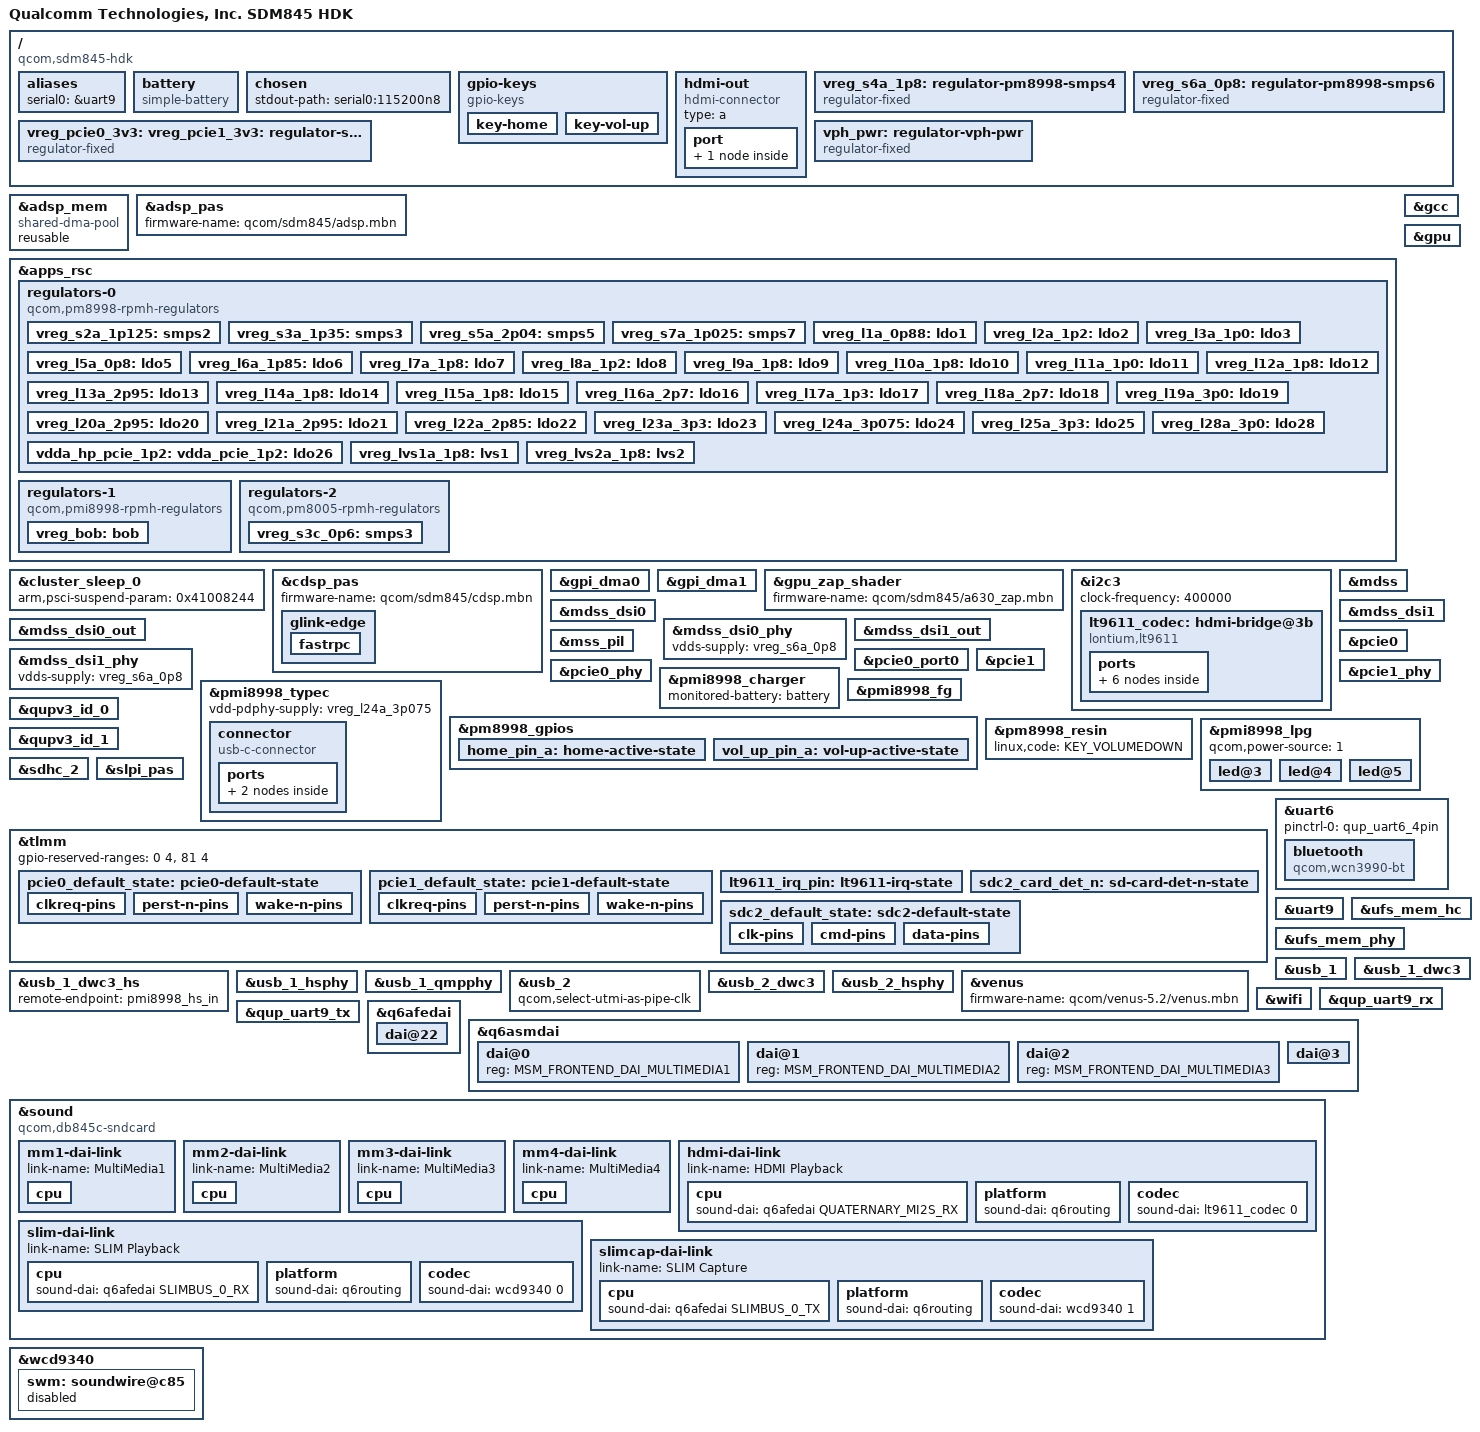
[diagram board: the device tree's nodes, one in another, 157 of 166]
// SPDX-License-Identifier: BSD-3-Clause
/*
 * Copyright (c) Qualcomm Technologies, Inc. and/or its subsidiaries.
 */

/dts-v1/;

#include <dt-bindings/arm/qcom,ids.h>
#include <dt-bindings/input/linux-event-codes.h>
#include <dt-bindings/interrupt-controller/irq.h>
#include <dt-bindings/leds/common.h>
#include <dt-bindings/pinctrl/qcom,pmic-gpio.h>
#include <dt-bindings/regulator/qcom,rpmh-regulator.h>
#include <dt-bindings/sound/qcom,q6afe.h>
#include <dt-bindings/sound/qcom,q6asm.h>
#include <dt-bindings/sound/qcom,wcd934x.h>
#include <dt-bindings/usb/pd.h>

#include "sdm845.dtsi"
#include "sdm845-wcd9340.dtsi"
#include "pm8005.dtsi"
#include "pm8998.dtsi"
#include "pmi8998.dtsi"

/ {
	model = "Qualcomm Technologies, Inc. SDM845 HDK";
	compatible = "qcom,sdm845-hdk", "qcom,sdm845";
	chassis-type = "embedded";

	aliases {
		serial0 = &uart9;
	};
	
	battery: battery {
		compatible = "simple-battery";
	};

	chosen {
		stdout-path = "serial0:115200n8";
	};

	gpio-keys {
		compatible = "gpio-keys";
		autorepeat;

		pinctrl-0 = <&home_pin_a>, <&vol_up_pin_a>;
		pinctrl-names = "default";

		key-home {
			label = "Home";
			linux,code = <KEY_HOMEPAGE>;
			gpios = <&pm8998_gpios 5 GPIO_ACTIVE_LOW>;
		};

		key-vol-up {
			label = "Volume Up";
			linux,code = <KEY_VOLUMEUP>;
			gpios = <&pm8998_gpios 6 GPIO_ACTIVE_LOW>;
		};
	};

	hdmi-out {
		compatible = "hdmi-connector";
		type = "a";

		port {
			hdmi_con: endpoint {
				remote-endpoint = <&lt9611_out>;
			};
		};
	};

	/*
	 * Apparently RPMh does not provide support for PM8998 S4 and S6
	 * because they are always-on; model them as fixed regulators.
	 */
	vreg_s4a_1p8: regulator-pm8998-smps4 {
		compatible = "regulator-fixed";
		regulator-name = "vreg_s4a_1p8";

		regulator-min-microvolt = <1800000>;
		regulator-max-microvolt = <1800000>;

		regulator-always-on;
		regulator-boot-on;

		vin-supply = <&vph_pwr>;
	};

	vreg_s6a_0p8: regulator-pm8998-smps6 {
		compatible = "regulator-fixed";
		regulator-name = "vreg_s6a_0p8";

		regulator-min-microvolt = <800000>;
		regulator-max-microvolt = <800000>;

		regulator-always-on;
		regulator-boot-on;

		vin-supply = <&vph_pwr>;
	};

	vreg_pcie0_3v3:
	vreg_pcie1_3v3:
	vreg_sys_bob_3p3: regulator-sys-bob {
		compatible = "regulator-fixed";
		regulator-name = "sys_bob";
		regulator-min-microvolt = <3300000>;
		regulator-max-microvolt = <3300000>;

		regulator-always-on;
		regulator-boot-on;

		/*
		 * SYS_BOB is powered on by vph_pwr and enabled by S4A_1P8.
		 * This is the least awkward way to describe it.
		 */
		vin-supply = <&vreg_s4a_1p8>;
	};

	vph_pwr: regulator-vph-pwr {
		compatible = "regulator-fixed";
		regulator-name = "vph_pwr";
		regulator-min-microvolt = <3700000>;
		regulator-max-microvolt = <3700000>;
	};
};

&adsp_mem {
	/* Convert the rigid firmware tracking partition into a flexible dynamic DMA pool */
	compatible = "shared-dma-pool";
	reusable;
};

&adsp_pas {
	firmware-name = "qcom/sdm845/adsp.mbn";

	status = "okay";
};

&apps_rsc {
	regulators-0 {
		compatible = "qcom,pm8998-rpmh-regulators";
		qcom,pmic-id = "a";

		vdd-s1-supply = <&vph_pwr>;
		vdd-s2-supply = <&vph_pwr>;
		vdd-s3-supply = <&vph_pwr>;
		vdd-s4-supply = <&vph_pwr>;
		vdd-s5-supply = <&vph_pwr>;
		vdd-s6-supply = <&vph_pwr>;
		vdd-s7-supply = <&vph_pwr>;
		vdd-s8-supply = <&vph_pwr>;
		vdd-s9-supply = <&vph_pwr>;
		vdd-s10-supply = <&vph_pwr>;
		vdd-s11-supply = <&vph_pwr>;
		vdd-s12-supply = <&vph_pwr>;
		vdd-s13-supply = <&vph_pwr>;
		vdd-l1-l27-supply = <&vreg_s7a_1p025>;
		vdd-l2-l8-l17-supply = <&vreg_s3a_1p35>;
		vdd-l3-l11-supply = <&vreg_s7a_1p025>;
		vdd-l4-l5-supply = <&vreg_s7a_1p025>;
		vdd-l6-supply = <&vph_pwr>;
		vdd-l7-l12-l14-l15-supply = <&vreg_s5a_2p04>;
		vdd-l9-supply = <&vreg_bob>;
		vdd-l10-l23-l25-supply = <&vreg_bob>;
		vdd-l13-l19-l21-supply = <&vreg_bob>;
		vdd-l16-l28-supply = <&vreg_bob>;
		vdd-l18-l22-supply = <&vreg_bob>;
		vdd-l20-l24-supply = <&vreg_bob>;
		vdd-l26-supply = <&vreg_s3a_1p35>;
		vin-lvs-1-2-supply = <&vreg_s4a_1p8>;

		vreg_s2a_1p125: smps2 {
			regulator-min-microvolt = <1100000>;
			regulator-max-microvolt = <1100000>;
		};

		vreg_s3a_1p35: smps3 {
			regulator-min-microvolt = <1352000>;
			regulator-max-microvolt = <1352000>;
		};

		vreg_s5a_2p04: smps5 {
			regulator-min-microvolt = <1904000>;
			regulator-max-microvolt = <2040000>;
		};

		vreg_s7a_1p025: smps7 {
			regulator-min-microvolt = <900000>;
			regulator-max-microvolt = <1028000>;
		};

		vreg_l1a_0p88: ldo1 {
			regulator-min-microvolt = <880000>;
			regulator-max-microvolt = <880000>;
			regulator-initial-mode = <RPMH_REGULATOR_MODE_HPM>;
		};

		vreg_l2a_1p2: ldo2 {
			regulator-min-microvolt = <1200000>;
			regulator-max-microvolt = <1200000>;
			regulator-initial-mode = <RPMH_REGULATOR_MODE_HPM>;
			regulator-always-on;
		};

		vreg_l3a_1p0: ldo3 {
			regulator-min-microvolt = <1000000>;
			regulator-max-microvolt = <1000000>;
			regulator-initial-mode = <RPMH_REGULATOR_MODE_HPM>;
		};

		vreg_l5a_0p8: ldo5 {
			regulator-min-microvolt = <800000>;
			regulator-max-microvolt = <800000>;
			regulator-initial-mode = <RPMH_REGULATOR_MODE_HPM>;
		};

		vreg_l6a_1p85: ldo6 {
			regulator-min-microvolt = <1856000>;
			regulator-max-microvolt = <1856000>;
			regulator-initial-mode = <RPMH_REGULATOR_MODE_HPM>;
		};

		vreg_l7a_1p8: ldo7 {
			regulator-min-microvolt = <1800000>;
			regulator-max-microvolt = <1800000>;
			regulator-initial-mode = <RPMH_REGULATOR_MODE_HPM>;
		};

		vreg_l8a_1p2: ldo8 {
			regulator-min-microvolt = <1200000>;
			regulator-max-microvolt = <1248000>;
			regulator-initial-mode = <RPMH_REGULATOR_MODE_HPM>;
		};

		vreg_l9a_1p8: ldo9 {
			regulator-min-microvolt = <1704000>;
			regulator-max-microvolt = <2928000>;
			regulator-initial-mode = <RPMH_REGULATOR_MODE_HPM>;
		};

		vreg_l10a_1p8: ldo10 {
			regulator-min-microvolt = <1704000>;
			regulator-max-microvolt = <2928000>;
			regulator-initial-mode = <RPMH_REGULATOR_MODE_HPM>;
		};

		vreg_l11a_1p0: ldo11 {
			regulator-min-microvolt = <1000000>;
			regulator-max-microvolt = <1048000>;
			regulator-initial-mode = <RPMH_REGULATOR_MODE_HPM>;
		};

		vreg_l12a_1p8: ldo12 {
			regulator-min-microvolt = <1800000>;
			regulator-max-microvolt = <1800000>;
			regulator-initial-mode = <RPMH_REGULATOR_MODE_HPM>;
		};

		vreg_l13a_2p95: ldo13 {
			regulator-min-microvolt = <1800000>;
			regulator-max-microvolt = <2960000>;
			regulator-initial-mode = <RPMH_REGULATOR_MODE_HPM>;
		};

		vreg_l14a_1p8: ldo14 {
			regulator-min-microvolt = <1800000>;
			regulator-max-microvolt = <1800000>;
			regulator-initial-mode = <RPMH_REGULATOR_MODE_HPM>;
		};

		vreg_l15a_1p8: ldo15 {
			regulator-min-microvolt = <1800000>;
			regulator-max-microvolt = <1800000>;
			regulator-initial-mode = <RPMH_REGULATOR_MODE_HPM>;
		};

		vreg_l16a_2p7: ldo16 {
			regulator-min-microvolt = <2704000>;
			regulator-max-microvolt = <2704000>;
			regulator-initial-mode = <RPMH_REGULATOR_MODE_HPM>;
		};

		vreg_l17a_1p3: ldo17 {
			regulator-min-microvolt = <1304000>;
			regulator-max-microvolt = <1304000>;
			regulator-initial-mode = <RPMH_REGULATOR_MODE_HPM>;
		};

		vreg_l18a_2p7: ldo18 {
			regulator-min-microvolt = <2704000>;
			regulator-max-microvolt = <2960000>;
			regulator-initial-mode = <RPMH_REGULATOR_MODE_HPM>;
		};

		vreg_l19a_3p0: ldo19 {
			regulator-min-microvolt = <2856000>;
			regulator-max-microvolt = <3104000>;
			regulator-initial-mode = <RPMH_REGULATOR_MODE_HPM>;
			regulator-boot-on;	// to see if this will help with the sensors
			regulator-always-on;
		};

		vreg_l20a_2p95: ldo20 {
			regulator-min-microvolt = <2704000>;
			regulator-max-microvolt = <2960000>;
			regulator-initial-mode = <RPMH_REGULATOR_MODE_HPM>;
		};

		vreg_l21a_2p95: ldo21 {
			regulator-min-microvolt = <2704000>;
			regulator-max-microvolt = <2960000>;
			regulator-initial-mode = <RPMH_REGULATOR_MODE_HPM>;
		};

		vreg_l22a_2p85: ldo22 {
			regulator-min-microvolt = <2864000>;
			regulator-max-microvolt = <3312000>;
			regulator-initial-mode = <RPMH_REGULATOR_MODE_HPM>;
		};

		vreg_l23a_3p3: ldo23 {
			regulator-min-microvolt = <3300000>;
			regulator-max-microvolt = <3312000>;
			regulator-initial-mode = <RPMH_REGULATOR_MODE_HPM>;
		};

		vreg_l24a_3p075: ldo24 {
			regulator-min-microvolt = <3088000>;
			regulator-max-microvolt = <3088000>;
			regulator-initial-mode = <RPMH_REGULATOR_MODE_HPM>;
		};

		vreg_l25a_3p3: ldo25 {
			regulator-min-microvolt = <3300000>;
			regulator-max-microvolt = <3312000>;
			regulator-initial-mode = <RPMH_REGULATOR_MODE_HPM>;
		};

		vdda_hp_pcie_1p2:
		vdda_pcie_1p2:
		vreg_l26a_1p2: ldo26 {
			regulator-min-microvolt = <1200000>;
			regulator-max-microvolt = <1200000>;
			regulator-initial-mode = <RPMH_REGULATOR_MODE_HPM>;
		};

		vreg_l28a_3p0: ldo28 {
			regulator-min-microvolt = <2856000>;
			regulator-max-microvolt = <3008000>;
			regulator-initial-mode = <RPMH_REGULATOR_MODE_HPM>;
		};

		vreg_lvs1a_1p8: lvs1 {
			regulator-min-microvolt = <1800000>;
			regulator-max-microvolt = <1800000>;
		};

		vreg_lvs2a_1p8: lvs2 {
			regulator-min-microvolt = <1800000>;
			regulator-max-microvolt = <1800000>;
		};
	};

	regulators-1 {
		compatible = "qcom,pmi8998-rpmh-regulators";
		qcom,pmic-id = "b";

		vdd-bob-supply = <&vph_pwr>;

		vreg_bob: bob {
			regulator-min-microvolt = <3312000>;
			regulator-max-microvolt = <3600000>;
			regulator-initial-mode = <RPMH_REGULATOR_MODE_AUTO>;
			regulator-allow-bypass;
		};
	};

	regulators-2 {
		compatible = "qcom,pm8005-rpmh-regulators";
		qcom,pmic-id = "c";

		vdd-s1-supply = <&vph_pwr>;
		vdd-s2-supply = <&vph_pwr>;
		vdd-s3-supply = <&vph_pwr>;
		vdd-s4-supply = <&vph_pwr>;

		vreg_s3c_0p6: smps3 {
			regulator-min-microvolt = <600000>;
			regulator-max-microvolt = <600000>;
		};
	};
};

&battery {
	charge-full-design-microamp-hours = <2970000>;
	voltage-min-design-microvolt = <3600000>;
	voltage-max-design-microvolt = <4400000>;
};


&cluster_sleep_0 {
	/* default, 0x4100c244, kills the board */
	arm,psci-suspend-param = <0x41008244>;
};

&cdsp_pas {
	status = "okay";
	
	firmware-name = "qcom/sdm845/cdsp.mbn";

	glink-edge {
		fastrpc {
			memory-region = <&fastrpc_mem>; 
			qcom,assign-all-mem;
		};
	};
};

&gcc {
	protected-clocks = <GCC_QSPI_CORE_CLK>,
			   <GCC_QSPI_CORE_CLK_SRC>,
			   <GCC_QSPI_CNOC_PERIPH_AHB_CLK>,
			   <GCC_LPASS_Q6_AXI_CLK>,
			   <GCC_LPASS_SWAY_CLK>;
};

&gpi_dma0 {
	status = "okay";
};

&gpi_dma1 {
	status = "okay";
};

&gpu {
	status = "okay";
};

&gpu_zap_shader {
	firmware-name = "qcom/sdm845/a630_zap.mbn";
};

&i2c3 {
	clock-frequency = <400000>;

	status = "okay";

	lt9611_codec: hdmi-bridge@3b {
		compatible = "lontium,lt9611";
		reg = <0x3b>;
		#sound-dai-cells = <1>;

		interrupts-extended = <&tlmm 113 IRQ_TYPE_EDGE_FALLING>;

		reset-gpios = <&tlmm 76 GPIO_ACTIVE_HIGH>;

		vdd-supply = <&vreg_s4a_1p8>;
		vcc-supply = <&vreg_sys_bob_3p3>;

		pinctrl-0 = <&lt9611_irq_pin>;
		pinctrl-names = "default";

		ports {
			#address-cells = <1>;
			#size-cells = <0>;

			port@0 {
				reg = <0>;

				lt9611_a: endpoint {
					remote-endpoint = <&mdss_dsi0_out>;
				};
			};

			port@1 {
				reg = <1>;

				lt9611_b: endpoint {
					remote-endpoint = <&mdss_dsi1_out>;
				};
			};

			port@2 {
				reg = <2>;

				lt9611_out: endpoint {
					remote-endpoint = <&hdmi_con>;
				};
			};
		};
	};
};

&mdss {
	status = "okay";
};

&mdss_dsi0 {
	vdda-supply = <&vreg_l26a_1p2>;

	qcom,dual-dsi-mode;
	qcom,master-dsi;

	status = "okay";
};

&mdss_dsi0_out {
	remote-endpoint = <&lt9611_a>;
	data-lanes = <0 1 2 3>;
};

&mdss_dsi0_phy {
	vdds-supply = <&vreg_s6a_0p8>;

	status = "okay";
};

&mdss_dsi1 {
	vdda-supply = <&vreg_l26a_1p2>;

	qcom,dual-dsi-mode;

	/* DSI1 is slave, so use DSI0 clocks */
	assigned-clock-parents = <&mdss_dsi0_phy DSI_BYTE_PLL_CLK>,
				 <&mdss_dsi0_phy DSI_PIXEL_PLL_CLK>;

	status = "okay";
};

&mdss_dsi1_out {
	remote-endpoint = <&lt9611_b>;
	data-lanes = <0 1 2 3>;
};

&mdss_dsi1_phy {
	vdds-supply = <&vreg_s6a_0p8>;

	status = "okay";
};

&mss_pil {
	firmware-name = "qcom/sdm845/mba.mbn", "qcom/sdm845/modem.mbn";

	status = "okay";
};

&pcie0 {
	status = "okay";
	vddpe-3v3-supply = <&vreg_pcie0_3v3>; 

	pinctrl-0 = <&pcie0_default_state>;
	pinctrl-names = "default";
	
	vdda-supply = <&vreg_l26a_1p2>; 
};

&pcie0_port0 {
	reset-gpios = <&tlmm 35 GPIO_ACTIVE_LOW>;
	wake-gpios = <&tlmm 37 GPIO_ACTIVE_HIGH>;
};

&pcie0_phy {
	vdda-phy-supply = <&vreg_l1a_0p88>;
	vdda-pll-supply = <&vreg_l26a_1p2>;

	status = "okay";
};

&pcie1 {
	perst-gpios = <&tlmm 102 GPIO_ACTIVE_LOW>;

	pinctrl-0 = <&pcie1_default_state>;
	pinctrl-names = "default";

	status = "okay";
};

&pcie1_phy {
	vdda-phy-supply = <&vreg_l1a_0p88>;
	vdda-pll-supply = <&vreg_l26a_1p2>;

	status = "okay";
};

&pmi8998_charger {
	status = "okay";

	monitored-battery = <&battery>;
};

&pmi8998_fg {
	status = "okay";

	monitored-battery = <&battery>;
	power-supplies = <&pmi8998_charger>;
};

&pmi8998_typec {
	status = "okay";

	vdd-pdphy-supply = <&vreg_l24a_3p075>;

	connector {
		compatible = "usb-c-connector";

		/*
		* Sink only for now, as the PMI8998 charger doesn't provide
		* the VBUS output yet. Switch to the dual power role with
		* source PDOs, try-power-role and vbus-supply once it is
		* supported.
		*/
		power-role = "sink";
		data-role = "dual";
		self-powered;

		sink-pdos = <PDO_FIXED(5000, 3000,
	                      PDO_FIXED_USB_COMM |
			      PDO_FIXED_DATA_SWAP)>;
		op-sink-microwatt = <15000000>;

		ports {
			#address-cells = <1>;
			#size-cells = <0>;

			port@0 {
				reg = <0>;
				pmi8998_hs_in: endpoint {
					remote-endpoint = <&usb_1_dwc3_hs>;
				};
			};
		};
	};
};

&pm8998_gpios {
	home_pin_a: home-active-state {
		pins = "gpio5";
		function = "normal";
		input-enable;
		bias-pull-up;
		qcom,drive-strength = <PMIC_GPIO_STRENGTH_NO>;
	};

	vol_up_pin_a: vol-up-active-state {
		pins = "gpio6";
		function = "normal";
		input-enable;
		bias-pull-up;
		qcom,drive-strength = <PMIC_GPIO_STRENGTH_NO>;
	};
};

&pm8998_resin {
	linux,code = <KEY_VOLUMEDOWN>;

	status = "okay";
};

&pmi8998_lpg {
	status = "okay";

	qcom,power-source = <1>;

	led@3 {
		reg = <3>;
		color = <LED_COLOR_ID_BLUE>;
		function = LED_FUNCTION_BLUETOOTH;
		linux,default-trigger = "bluetooth-power";
	};

	led@4 {
		reg = <4>;
		color = <LED_COLOR_ID_GREEN>;
		function = LED_FUNCTION_HEARTBEAT;
		linux,default-trigger = "heartbeat";
		function-enumerator = <2>;
	};

	led@5 {
		reg = <5>;
		color = <LED_COLOR_ID_RED>;
		function = LED_FUNCTION_INDICATOR;
		function-enumerator = <1>;
	};
};

&qupv3_id_0 {
	status = "okay";
};

&qupv3_id_1 {
	status = "okay";
};

&sdhc_2 {
	pinctrl-0 = <&sdc2_default_state &sdc2_card_det_n>;
	pinctrl-names = "default";

	vmmc-supply = <&vreg_l21a_2p95>;
	vqmmc-supply = <&vreg_l13a_2p95>;

	cd-gpios = <&tlmm 126 GPIO_ACTIVE_LOW>;
	bus-width = <4>;

	status = "okay";
};

&slpi_pas {
	firmware-name = "qcom/sdm845/Qualcomm/SDM845-HDK/slpi.mbn";
	px-supply = <&vreg_l19a_3p0>;

	status = "okay";
};

&tlmm {
	gpio-reserved-ranges = <0 4>, /* SPI (eSE - embedded Secure Element) */
			       <81 4>; /* SPI (fingerprint reader) */

	pcie0_default_state: pcie0-default-state {
		clkreq-pins {
			pins = "gpio36";
			function = "pci_e0";
			bias-pull-up;
		};

		perst-n-pins {
			pins = "gpio35";
			function = "gpio";
			drive-strength = <2>;
			bias-pull-down;
		};

		wake-n-pins {
			pins = "gpio37";
			function = "gpio";
			drive-strength = <2>;
			bias-pull-up;
		};
	};

	pcie1_default_state: pcie1-default-state {
		clkreq-pins {
			pins = "gpio103";
			function = "pci_e1";
			bias-pull-up;
		};

		perst-n-pins {
			pins = "gpio102";
			function = "gpio";
			drive-strength = <16>;
			bias-pull-down;
		};

		wake-n-pins {
			pins = "gpio104";
			function = "gpio";
			drive-strength = <2>;
			bias-pull-up;
		};
	};

	lt9611_irq_pin: lt9611-irq-state {
		pins = "gpio113";
		function = "gpio";
		bias-disable;
	};

	sdc2_card_det_n: sd-card-det-n-state {
		pins = "gpio126";
		function = "gpio";
		bias-pull-up;
	};

	sdc2_default_state: sdc2-default-state {
		clk-pins {
			pins = "sdc2_clk";
			bias-disable;

			/*
			 * It seems that mmc_test reports errors if drive
			 * strength is not 16 on clk, cmd, and data pins.
			 */
			drive-strength = <16>;
		};

		cmd-pins {
			pins = "sdc2_cmd";
			bias-pull-up;
			drive-strength = <10>;
		};

		data-pins {
			pins = "sdc2_data";
			bias-pull-up;
			drive-strength = <10>;
		};
	};
};

&uart6 {
	pinctrl-0 = <&qup_uart6_4pin>;

	status = "okay";

	bluetooth {
		compatible = "qcom,wcn3990-bt";

		vddio-supply = <&vreg_s4a_1p8>;
		vddxo-supply = <&vreg_l7a_1p8>;
		vddrf-supply = <&vreg_l17a_1p3>;
		vddch0-supply = <&vreg_l25a_3p3>;
		max-speed = <3200000>;
	};
};

&uart9 {
	status = "okay";
};

&ufs_mem_hc {
	status = "okay";

	reset-gpios = <&tlmm 150 GPIO_ACTIVE_LOW>;

	vcc-supply = <&vreg_l20a_2p95>;
	vcc-max-microamp = <800000>;
};

&ufs_mem_phy {
	status = "okay";

	vdda-phy-supply = <&vreg_l1a_0p88>;
	vdda-pll-supply = <&vreg_l26a_1p2>;
};

&usb_1 {
	status = "okay";
};

&usb_1_dwc3 {
	/* Until PMI8998 supports OTG */
	dr_mode = "otg";
	usb-role-switch;
};

&usb_1_dwc3_hs {
	remote-endpoint = <&pmi8998_hs_in>;
};

&usb_1_hsphy {
	status = "okay";

	vdd-supply = <&vreg_l1a_0p88>;
	vdda-pll-supply = <&vreg_l12a_1p8>;
	vdda-phy-dpdm-supply = <&vreg_l24a_3p075>;

	qcom,imp-res-offset-value = <8>;
	qcom,hstx-trim-value = <QUSB2_V2_HSTX_TRIM_21_6_MA>;
	qcom,preemphasis-level = <QUSB2_V2_PREEMPHASIS_5_PERCENT>;
	qcom,preemphasis-width = <QUSB2_V2_PREEMPHASIS_WIDTH_HALF_BIT>;
};

&usb_1_qmpphy {
	vdda-phy-supply = <&vreg_l1a_0p88>;
	vdda-pll-supply = <&vreg_l26a_1p2>;

	status = "okay";
};

/* HS only */
&usb_2 {
	qcom,select-utmi-as-pipe-clk;

	status = "okay";
};

&usb_2_dwc3 {
	maximum-speed = "high-speed";
	phys = <&usb_2_hsphy>;
	phy-names = "usb2-phy";

	dr_mode = "host";
};

&usb_2_hsphy {
	vdd-supply = <&vreg_l1a_0p88>;
	vdda-pll-supply = <&vreg_l12a_1p8>;
	vdda-phy-dpdm-supply = <&vreg_l24a_3p075>;

	qcom,imp-res-offset-value = <8>;
	qcom,hstx-trim-value = <QUSB2_V2_HSTX_TRIM_22_8_MA>;

	status = "okay";
};

&venus {
	firmware-name = "qcom/venus-5.2/venus.mbn";

	status = "okay";
};

&wifi {
	vdd-0.8-cx-mx-supply = <&vreg_l5a_0p8>;
	vdd-1.8-xo-supply = <&vreg_l7a_1p8>;
	vdd-1.3-rfa-supply = <&vreg_l17a_1p3>;
	vdd-3.3-ch0-supply = <&vreg_l25a_3p3>;
	vdd-3.3-ch1-supply = <&vreg_l23a_3p3>;

	qcom,snoc-host-cap-8bit-quirk;
	qcom,calibration-variant = "Qualcomm_sdm845hdk";

	status = "okay";
};

/* PINCTRL - additions to nodes defined in sdm845.dtsi */
&qup_uart9_rx {
	drive-strength = <2>;
	bias-pull-up;
};

&qup_uart9_tx {
	drive-strength = <2>;
	bias-disable;
};

/* QUAT I2S Uses 4 I2S SD Lines for audio on LT9611 HDMI Bridge */
&q6afedai {
	dai@22 {
		/delete-property/ iommus;
		qcom,no-shm-bridge;
		qcom,no-64bit-addresses;

		reg = <QUATERNARY_MI2S_RX>;
		qcom,sd-lines = <0 1 2 3>;
	};
};

&q6asmdai {
	dai@0 {
		reg = <MSM_FRONTEND_DAI_MULTIMEDIA1>;
	};

	dai@1 {
		reg = <MSM_FRONTEND_DAI_MULTIMEDIA2>;
	};

	dai@2 {
		reg = <MSM_FRONTEND_DAI_MULTIMEDIA3>;
	};

	dai@3 {
		reg = <MSM_FRONTEND_DAI_MULTIMEDIA4>;
		direction = <2>;
		is-compress-dai;
	};
};


&sound {
	compatible = "qcom,db845c-sndcard", "qcom,sdm845-sndcard";
	pinctrl-0 = <&quat_mi2s_active
			 &quat_mi2s_sd0_active
			 &quat_mi2s_sd1_active
			 &quat_mi2s_sd2_active
			 &quat_mi2s_sd3_active>;
	pinctrl-names = "default";
	model = "HDK845";
	
	/*
	* this routing is for the sdm845-hdk with audio-extension boards installed
	*audio-routing =
	*	"RX_BIAS", "MCLK",
	*	"AMIC1", "MIC BIAS1",
	*	"AMIC2", "MIC BIAS2",
	*	"DMIC0", "MIC BIAS1",
	*	"DMIC1", "MIC BIAS1",
	*	"DMIC2", "MIC BIAS3",
	*	"DMIC3", "MIC BIAS3",
	*	"SpkrLeft IN", "SPK1 OUT",
	*	"SpkrRight IN", "SPK2 OUT";
	*
	* below routing is for the sdm845-hdk with just 3.5mm headset output
	*/
	
	audio-routing =
		"RX_BIAS", "MCLK",
		"AMIC1", "MIC BIAS1",
		"AMIC2", "MIC BIAS2";
	
	mm1-dai-link {
		link-name = "MultiMedia1";
		cpu {
			sound-dai = <&q6asmdai  MSM_FRONTEND_DAI_MULTIMEDIA1>;
		};
	};

	mm2-dai-link {
		link-name = "MultiMedia2";
		cpu {
			sound-dai = <&q6asmdai  MSM_FRONTEND_DAI_MULTIMEDIA2>;
		};
	};

	mm3-dai-link {
		link-name = "MultiMedia3";
		cpu {
			sound-dai = <&q6asmdai  MSM_FRONTEND_DAI_MULTIMEDIA3>;
		};
	};

	mm4-dai-link {
		link-name = "MultiMedia4";
		cpu {
			sound-dai = <&q6asmdai  MSM_FRONTEND_DAI_MULTIMEDIA4>;
		};
	};

	hdmi-dai-link {
		link-name = "HDMI Playback";
		cpu {
			sound-dai = <&q6afedai QUATERNARY_MI2S_RX>;
		};

		platform {
			sound-dai = <&q6routing>;
		};

		codec {
			sound-dai = <&lt9611_codec 0>;
		};
	};

	slim-dai-link {
		link-name = "SLIM Playback";
		cpu {
			sound-dai = <&q6afedai SLIMBUS_0_RX>;
		};

		platform {
			sound-dai = <&q6routing>;
		};

		codec {
			/*
			*this codec list requires the audio-extension boards for the sdm845-hdk
			*sound-dai = <&left_spkr>, <&right_spkr>, <&swm 0>, <&wcd9340 0>;
			*
			*below list is for sdm845-hdk with just the 3.5mm headset output
			*/
			sound-dai = <&wcd9340 0>;
		};
	};

	slimcap-dai-link {
		link-name = "SLIM Capture";
		cpu {
			sound-dai = <&q6afedai SLIMBUS_0_TX>;
		};

		platform {
			sound-dai = <&q6routing>;
		};

		codec {
			sound-dai = <&wcd9340 1>;
		};
	};
};

&wcd9340 {
	reset-gpios = <&tlmm 64 GPIO_ACTIVE_HIGH>;
	vdd-buck-supply = <&vreg_s4a_1p8>;
	vdd-buck-sido-supply = <&vreg_s4a_1p8>;
	vdd-tx-supply = <&vreg_s4a_1p8>;
	vdd-rx-supply = <&vreg_s4a_1p8>;
	vdd-io-supply = <&vreg_s4a_1p8>;

	clocks = <&rpmhcc RPMH_LN_BB_CLK2>;
	clock-names = "extclk";

	swm: soundwire@c85 {
		status = "disabled";
	};
};

